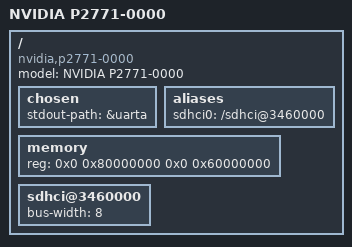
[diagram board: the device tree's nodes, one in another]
#include "tegra186.dtsi"

/ {
	model = "NVIDIA P2771-0000";
	compatible = "nvidia,p2771-0000", "nvidia,tegra186";

	chosen {
		stdout-path = &uarta;
	};

	aliases {
		sdhci0 = "/sdhci@3460000";
	};

	memory {
		reg = <0x0 0x80000000 0x0 0x60000000>;
	};

	sdhci@3460000 {
		status = "okay";
		bus-width = <8>;
	};
};
